BO_ 213 EngineData: 2 EngineECU
    SG_ RPM: 0|8@1+ (1,0) [0|5000] "rpm" TransECU
    SG_ TempE: 8|8@1+ (1,-40) [0|240] "deg" TransECU

BO_ 126 Transmission: 2 TransECU
    SG_ TempT: 0|8@1+ (1,-40) [0|240] "deg" EngineECU
    SG_ Gear: 8|8@1+ (1,0) [0|4] "" EngineECU
VAL_ 126 Gear 0 "Neutral" 1 "Drive" 2 "Reverse" 3 "Sport" 4 "Traction";

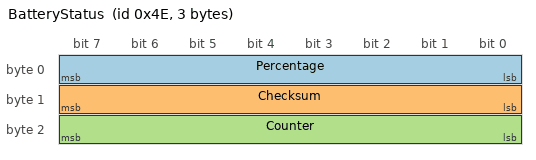
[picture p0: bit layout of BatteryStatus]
BO_ 78 BatteryStatus: 3 BatteryECU
    SG_ Percentage: 0|8@1+ (1,0) [0|100] "%" ECU2
    SG_ Checksum: 8|8@1+ (1,0) [0|255] "" ECU2
    SG_ Counter: 16|8@1+ (1,0) [0|15] "" ECU2
